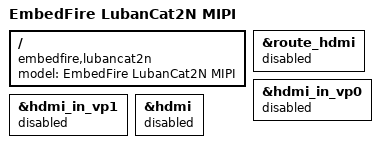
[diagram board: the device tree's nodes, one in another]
// SPDX-License-Identifier: (GPL-2.0+ OR MIT)
/*
 * Copyright (c) 2020 Rockchip Electronics Co., Ltd.
 *
 */

/dts-v1/;

#include "rk3568-lubancat2-n.dts"
#include "rk3568-lubancat-mipi-dsi0-ebf410125_1080p.dtsi"

/ {
	model = "EmbedFire LubanCat2N MIPI";
	compatible = "embedfire,lubancat2n", "rockchip,rk3568";
};

&route_hdmi {
	status = "disabled";
};

&hdmi_in_vp0 {
	status = "disabled";
};

&hdmi_in_vp1 {
	status = "disabled";
};

&hdmi {
	status = "disabled";
};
